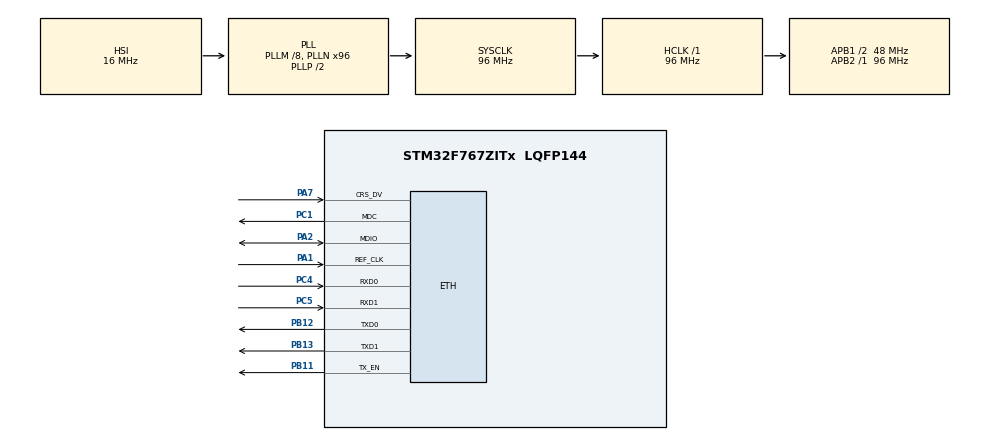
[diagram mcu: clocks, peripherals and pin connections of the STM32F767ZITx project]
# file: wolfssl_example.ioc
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ETH.MediaInterface=HAL_ETH_RMII_MODE
Mcu.Family=STM32F7
Mcu.Name=STM32F767ZITx
Mcu.Package=LQFP144
NVIC.PriorityGroup=NVIC_PRIORITYGROUP_4
PA1.Mode=RMII
PA1.Signal=ETH_REF_CLK
PA13.Mode=Serial_Wire
PA13.Signal=SYS_JTMS-SWDIO
PA14.Mode=Serial_Wire
PA14.Signal=SYS_JTCK-SWCLK
PA2.Mode=RMII
PA2.Signal=ETH_MDIO
PA7.Mode=RMII
PA7.Signal=ETH_CRS_DV
PB11.Mode=RMII
PB11.Signal=ETH_TX_EN
PB12.Mode=RMII
PB12.Signal=ETH_TXD0
PB13.Mode=RMII
PB13.Signal=ETH_TXD1
PC1.Mode=RMII
PC1.Signal=ETH_MDC
PC4.Mode=RMII
PC4.Signal=ETH_RXD0
PC5.Mode=RMII
PC5.Signal=ETH_RXD1
ProjectManager.HeapSize=0x200
ProjectManager.StackSize=0x400
ProjectManager.TargetToolchain=Makefile
RCC.AHBFreq_Value=96000000
RCC.APB1CLKDivider=RCC_HCLK_DIV2
RCC.APB1Freq_Value=48000000
RCC.APB1TimFreq_Value=96000000
RCC.APB2Freq_Value=96000000
RCC.APB2TimFreq_Value=96000000
RCC.CortexFreq_Value=96000000
RCC.HCLKFreq_Value=96000000
RCC.HSE_VALUE=25000000
RCC.HSI_VALUE=16000000
RCC.LSE_VALUE=32768
RCC.PLLM=8
RCC.PLLN=96
RCC.PLLQ=4
RCC.SYSCLKFreq_VALUE=96000000
RCC.SYSCLKSource=RCC_SYSCLKSOURCE_PLLCLK
RCC.USBFreq_Value=48000000
RCC.VCOOutputFreq_Value=192000000
VP_RNG_VS_RNG.Mode=RNG_Activate
VP_wolfSSL.I-CUBE-wolfSSL_VS_wolfSSLJjwolfSSL_5.8.2_5.8.2.Mode=wolfSSLJjwolfSSL
board=custom
wolfSSL.I-CUBE-wolfSSL.5.8.2.WOLF_CONF_AESCBC=0
wolfSSL.I-CUBE-wolfSSL.5.8.2.WOLF_CONF_DEBUG=1
wolfSSL.I-CUBE-wolfSSL.5.8.2.WOLF_CONF_MATH=1
wolfSSL.I-CUBE-wolfSSL.5.8.2.WOLF_CONF_WOLFCRYPT_ONLY=1
wolfSSL.I-CUBE-wolfSSL.5.8.2.wolfSSLCcwolfSSLJjwolfCryptJjCore=true
wolfSSL.I-CUBE-wolfSSL.5.8.2.wolfSSLCcwolfSSLJjwolfSSLJjCore=true

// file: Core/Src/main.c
/* USER CODE BEGIN Header */
/**
  ******************************************************************************
  * @file           : main.c
  * @brief          : Main program body
  ******************************************************************************
  * @attention
  *
  * Copyright (c) 2025 STMicroelectronics.
  * All rights reserved.
  *
  * This software is licensed under terms that can be found in the LICENSE file
  * in the root directory of this software component.
  * If no LICENSE file comes with this software, it is provided AS-IS.
  *
  ******************************************************************************
  */
/* USER CODE END Header */
#include "main.h"
#include "string.h"

/* USER CODE BEGIN PM */
#ifndef STM32F767xx
#error "STM32F767xx not defined!"
#endif // !STM32F767xx
/* USER CODE END PM */

#if defined ( __ICCARM__ ) /*!< IAR Compiler */
#pragma location=0x2007c000
ETH_DMADescTypeDef  DMARxDscrTab[ETH_RX_DESC_CNT]; /* Ethernet Rx DMA Descriptors */
#pragma location=0x2007c0a0
ETH_DMADescTypeDef  DMATxDscrTab[ETH_TX_DESC_CNT]; /* Ethernet Tx DMA Descriptors */

#elif defined ( __CC_ARM )  /* MDK ARM Compiler */

__attribute__((at(0x2007c000))) ETH_DMADescTypeDef  DMARxDscrTab[ETH_RX_DESC_CNT]; /* Ethernet Rx DMA Descriptors */
__attribute__((at(0x2007c0a0))) ETH_DMADescTypeDef  DMATxDscrTab[ETH_TX_DESC_CNT]; /* Ethernet Tx DMA Descriptors */

#elif defined ( __GNUC__ ) /* GNU Compiler */
ETH_DMADescTypeDef DMARxDscrTab[ETH_RX_DESC_CNT] __attribute__((section(".RxDecripSection"))); /* Ethernet Rx DMA Descriptors */
ETH_DMADescTypeDef DMATxDscrTab[ETH_TX_DESC_CNT] __attribute__((section(".TxDecripSection")));   /* Ethernet Tx DMA Descriptors */

#endif

ETH_TxPacketConfig TxConfig;

ETH_HandleTypeDef heth;

RNG_HandleTypeDef hrng;

void SystemClock_Config(void);
static void MX_GPIO_Init(void);
static void MX_ETH_Init(void);
static void MX_RNG_Init(void);

int main(void)
{

  /* MCU Configuration--------------------------------------------------------*/

  /* Reset of all peripherals, Initializes the Flash interface and the Systick. */
  HAL_Init();

  /* Configure the system clock */
  SystemClock_Config();

  /* Initialize all configured peripherals */
  MX_GPIO_Init();
  MX_ETH_Init();
  MX_RNG_Init();

  /* Infinite loop */
  while (1)
  {

  }
}

void SystemClock_Config(void)
{
  RCC_OscInitTypeDef RCC_OscInitStruct = {0};
  RCC_ClkInitTypeDef RCC_ClkInitStruct = {0};

  /** Configure the main internal regulator output voltage
  */
  __HAL_RCC_PWR_CLK_ENABLE();
  __HAL_PWR_VOLTAGESCALING_CONFIG(PWR_REGULATOR_VOLTAGE_SCALE3);

  /** Initializes the RCC Oscillators according to the specified parameters
  * in the RCC_OscInitTypeDef structure.
  */
  RCC_OscInitStruct.OscillatorType = RCC_OSCILLATORTYPE_HSI;
  RCC_OscInitStruct.HSIState = RCC_HSI_ON;
  RCC_OscInitStruct.HSICalibrationValue = RCC_HSICALIBRATION_DEFAULT;
  RCC_OscInitStruct.PLL.PLLState = RCC_PLL_ON;
  RCC_OscInitStruct.PLL.PLLSource = RCC_PLLSOURCE_HSI;
  RCC_OscInitStruct.PLL.PLLM = 8;
  RCC_OscInitStruct.PLL.PLLN = 96;
  RCC_OscInitStruct.PLL.PLLP = RCC_PLLP_DIV2;
  RCC_OscInitStruct.PLL.PLLQ = 4;
  RCC_OscInitStruct.PLL.PLLR = 2;
  if (HAL_RCC_OscConfig(&RCC_OscInitStruct) != HAL_OK)
  {
    Error_Handler();
  }

  /** Activate the Over-Drive mode
  */
  if (HAL_PWREx_EnableOverDrive() != HAL_OK)
  {
    Error_Handler();
  }

  /** Initializes the CPU, AHB and APB buses clocks
  */
  RCC_ClkInitStruct.ClockType = RCC_CLOCKTYPE_HCLK|RCC_CLOCKTYPE_SYSCLK
                              |RCC_CLOCKTYPE_PCLK1|RCC_CLOCKTYPE_PCLK2;
  RCC_ClkInitStruct.SYSCLKSource = RCC_SYSCLKSOURCE_PLLCLK;
  RCC_ClkInitStruct.AHBCLKDivider = RCC_SYSCLK_DIV1;
  RCC_ClkInitStruct.APB1CLKDivider = RCC_HCLK_DIV2;
  RCC_ClkInitStruct.APB2CLKDivider = RCC_HCLK_DIV1;

  if (HAL_RCC_ClockConfig(&RCC_ClkInitStruct, FLASH_LATENCY_3) != HAL_OK)
  {
    Error_Handler();
  }
}

static void MX_ETH_Init(void)
{

   static uint8_t MACAddr[6];

  heth.Instance = ETH;
  MACAddr[0] = 0x00;
  MACAddr[1] = 0x80;
  MACAddr[2] = 0xE1;
  MACAddr[3] = 0x00;
  MACAddr[4] = 0x00;
  MACAddr[5] = 0x00;
  heth.Init.MACAddr = &MACAddr[0];
  heth.Init.MediaInterface = HAL_ETH_RMII_MODE;
  heth.Init.TxDesc = DMATxDscrTab;
  heth.Init.RxDesc = DMARxDscrTab;
  heth.Init.RxBuffLen = 1524;

  if (HAL_ETH_Init(&heth) != HAL_OK)
  {
    Error_Handler();
  }

  memset(&TxConfig, 0 , sizeof(ETH_TxPacketConfig));
  TxConfig.Attributes = ETH_TX_PACKETS_FEATURES_CSUM | ETH_TX_PACKETS_FEATURES_CRCPAD;
  TxConfig.ChecksumCtrl = ETH_CHECKSUM_IPHDR_PAYLOAD_INSERT_PHDR_CALC;
  TxConfig.CRCPadCtrl = ETH_CRC_PAD_INSERT;

}

static void MX_RNG_Init(void)
{

  hrng.Instance = RNG;
  if (HAL_RNG_Init(&hrng) != HAL_OK)
  {
    Error_Handler();
  }

}

static void MX_GPIO_Init(void)
{

  /* GPIO Ports Clock Enable */
  __HAL_RCC_GPIOC_CLK_ENABLE();
  __HAL_RCC_GPIOA_CLK_ENABLE();
  __HAL_RCC_GPIOB_CLK_ENABLE();

}

void Error_Handler(void)
{
  __disable_irq();
  while (1)
  {
  }
}
